# STM32L011D3P6 register map
File version: 1.0
STM32L011D3P6,STM32L011D4P6,STM32L011D4P7,STM32L011E3Y6,STM32L011E4Y6,STM32L011F3P3,STM32L011F3P6,STM32L011F3P7,STM32L011F3U3,STM32L011F3U6,STM32L011F3U7,STM32L011F4P3,STM32L011F4P6,STM32L011F4P7,STM32L011F4U3,STM32L011F4U6,STM32L011F4U7,STM32L011G3U6,STM32L011G4U6,STM32L011G4U7,STM32L011K3T3,STM32L011K3T6,STM32L011K3T7,STM32L011K3U6,STM32L011K4T3,STM32L011K4T6,STM32L011K4T7,STM32L011K4U3,STM32L011K4U6,STM32L011K4U7,STM32L021D4P3,STM32L021D4P6,STM32L021D4P7,STM32L021F4P6,STM32L021F4U6,STM32L021F4U7,STM32L021G4U6,STM32L021G4U7,STM32L021K4T6,STM32L021K4T7,STM32L021K4U6,STM32L031C4T6,STM32L031C4U6,STM32L031C6T3,STM32L031C6T6,STM32L031C6T7,STM32L031C6U3,STM32L031C6U6,STM32L031C6U7,STM32L031E4Y6,STM32L031E6Y3,STM32L031E6Y6,STM32L031E6Y7,STM32L031F4P3,STM32L031F4P6,STM32L031F4P7,STM32L031F6P6,STM32L031F6P7,STM32L031G4U6,STM32L031G6U3,STM32L031G6U3S,STM32L031G6U6,STM32L031G6U6S,STM32L031G6U7,STM32L031G6U7S,STM32L031K4T3,STM32L031K4T6,STM32L031K4T7,STM32L031K4U6,STM32L031K6T3,STM32L031K6T6,STM32L031K6T7,STM32L031K6U3,STM32L031K6U6,STM32L031K6U7,STM32L041C4T6,STM32L041C4T7,STM32L041C6T6,STM32L041C6T7,STM32L041C6U6,STM32L041C6U7,STM32L041E6Y3,STM32L041E6Y6,STM32L041E6Y7,STM32L041F6P6,STM32L041F6P7,STM32L041G6U6,STM32L041G6U6S,STM32L041G6U7,STM32L041G6U7S,STM32L041K6T3,STM32L041K6T6,STM32L041K6T7,STM32L041K6U3,STM32L041K6U6,STM32L041K6U7,STM32L051C6T6,STM32L051C6U6,STM32L051C8T3,STM32L051C8T6,STM32L051C8T7,STM32L051C8U3,STM32L051C8U6,STM32L051C8U7,STM32L051K6T6,STM32L051K6U6,STM32L051K8
Registers are 32-bit, access not given, reset 0x0 unless marked. A register's access mark holds for its fields unless they carry their own. Offsets are from the block's base; lines under a group give offsets from that group; [hi:lo] are bit positions; {n}, {i} and the like mark numbered series; 'fields as' and 'values as' point back to an identical list; <NAME> marks a mode.

## Memory map
0x40000000 TIM2
0x40000400 TIM3
0x40001000 TIM6
0x40001400 TIM7
0x40002800 RTC
0x40002800 BKP
0x40002C00 WWDG
0x40003000 IWDG
0x40003800 SPI2
0x40004400 USART2
0x40004800 LPUART1
0x40004C00 USART4
0x40005000 USART5
0x40005400 I2C1
0x40005800 I2C2
0x40007000 PWR
0x40007800 I2C3
0x40007C00 LPTIM1
0x40010000 COMP
0x40010000 SYSCFG
0x40010400 EXTI
0x40010800 TIM21
0x40011400 TIM22
0x40011C00 FW
0x40012400 ADC1
0x40013000 SPI1
0x40013800 USART1
0x40015800 DBG
0x40020000 DMA1
0x40021000 RCC
0x40022000 FLASH
0x40023000 CRC
0x40026000 AES
0x50000000 GPIOA
0x50000400 GPIOB
0x50000800 GPIOC
0x50000C00 GPIOD
0x50001000 GPIOE
0x50001C00 GPIOH

## TIM2
Base 0x40000000
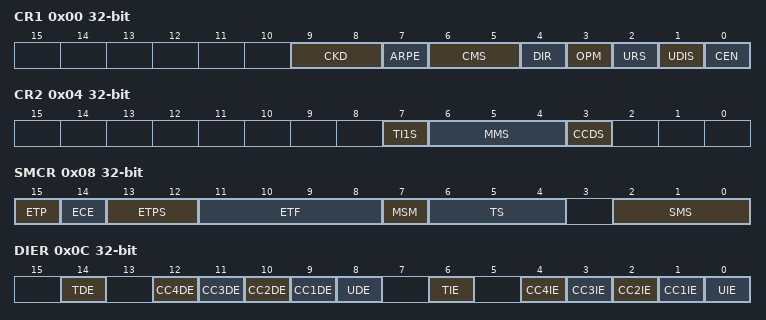
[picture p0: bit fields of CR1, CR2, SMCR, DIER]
0x00 CR1
  [9:8] CKD, [7] ARPE, [6:5] CMS, [4] DIR, [3] OPM, [2] URS, [1] UDIS, [0] CEN
0x04 CR2
  [7] TI1S, [6:4] MMS, [3] CCDS
0x08 SMCR
  [15] ETP, [14] ECE, [13:12] ETPS, [11:8] ETF, [7] MSM, [6:4] TS, [2:0] SMS
0x0C DIER
  [14] TDE, [n+8] CC{n}DE (n=1..4), [8] UDE, [6] TIE, [n] CC{n}IE (n=1..4), [0] UIE
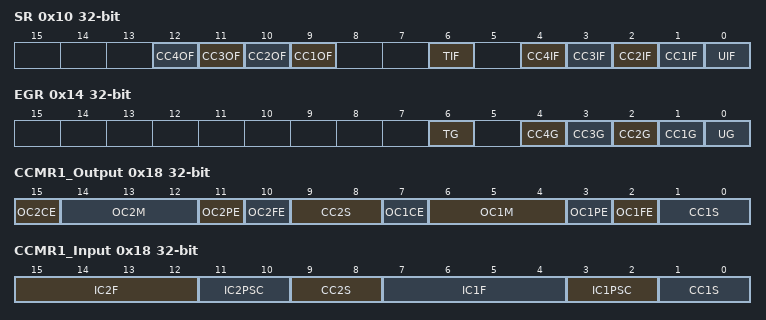
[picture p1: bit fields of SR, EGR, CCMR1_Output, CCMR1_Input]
0x10 SR
  [n+8] CC{n}OF (n=1..4), [6] TIF, [n] CC{n}IF (n=1..4), [0] UIF
0x14 EGR
  [6] TG, [n] CC{n}G (n=1..4), [0] UG
0x18 CCMR1_Output
  [15] OC2CE, [14:12] OC2M, [11] OC2PE, [10] OC2FE, [9:8] CC2S, [7] OC1CE, [6:4] OC1M, [3] OC1PE, [2] OC1FE, [1:0] CC1S
0x18 CCMR1_Input
  [15:12] IC2F, [11:10] IC2PSC, [9:8] CC2S, [7:4] IC1F, [3:2] IC1PSC, [1:0] CC1S
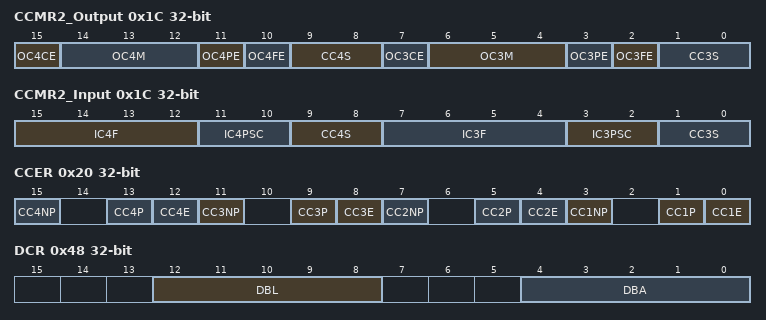
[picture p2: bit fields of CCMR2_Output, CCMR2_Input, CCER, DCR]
0x1C CCMR2_Output
  [15] OC4CE, [14:12] OC4M, [11] OC4PE, [10] OC4FE, [9:8] CC4S, [7] OC3CE, [6:4] OC3M, [3] OC3PE, [2] OC3FE, [1:0] CC3S
0x1C CCMR2_Input
  [15:12] IC4F, [11:10] IC4PSC, [9:8] CC4S, [7:4] IC3F, [3:2] IC3PSC, [1:0] CC3S
0x20 CCER
  [4n-1] CC{n}NP (n=1..4), [4n-3] CC{n}P (n=1..4), [4n-4] CC{n}E (n=1..4)
0x24 CNT
  [15:0] CNT
0x28 PSC
  [15:0] PSC
0x2C ARR
  [15:0] ARR
{0x30+4i} CCR{i} (i=1..4)
  [15:0] CCR{i}
0x48 DCR
  [12:8] DBL, [4:0] DBA
0x4C DMAR
  [15:0] DMAB
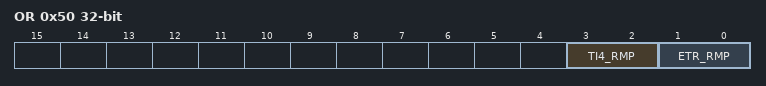
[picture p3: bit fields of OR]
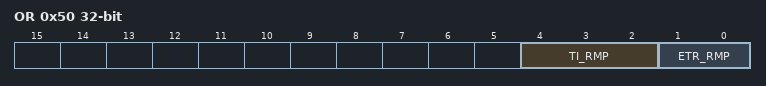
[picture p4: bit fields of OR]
0x50 OR
  [3:2] TI4_RMP, [1:0] ETR_RMP

## TIM3
Base 0x40000400
Registers as TIM2; these are added or differ:
0x50 OR
  [4:2] TI_RMP, [1:0] ETR_RMP

## TIM6
Base 0x40001000
Same registers: TIM7 0x40001400
0x00 CR1
0x04 CR2
0x0C DIER
0x10 SR
0x14 EGR
0x24 CNT
0x28 PSC
0x2C ARR
